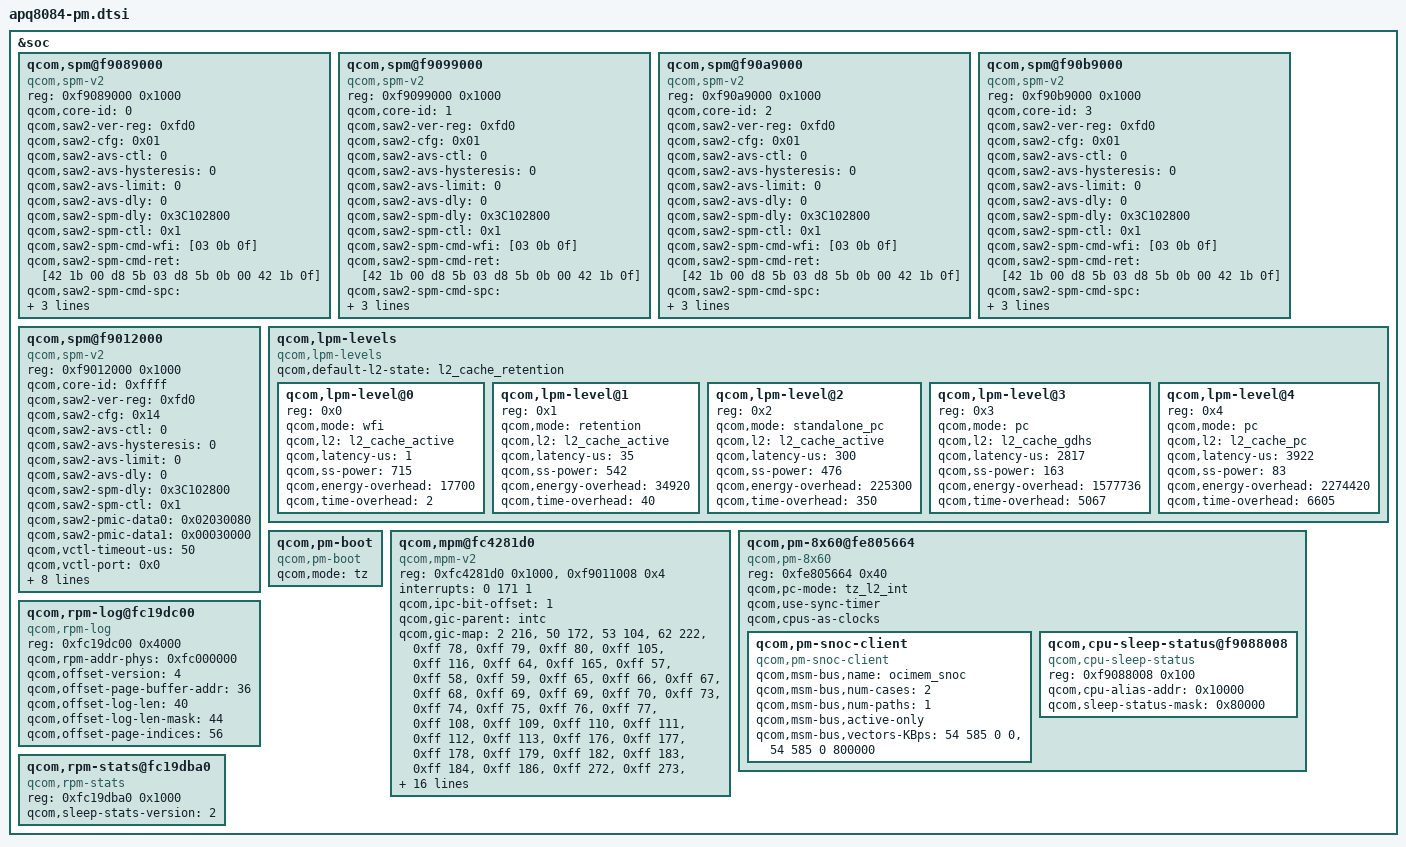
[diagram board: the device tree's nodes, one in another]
/* Copyright (c) 2013, The Linux Foundation. All rights reserved.
 *
 * This program is free software; you can redistribute it and/or modify
 * it under the terms of the GNU General Public License version 2 and
 * only version 2 as published by the Free Software Foundation.
 *
 * This program is distributed in the hope that it will be useful,
 * but WITHOUT ANY WARRANTY; without even the implied warranty of
 * MERCHANTABILITY or FITNESS FOR A PARTICULAR PURPOSE.  See the
 * GNU General Public License for more details.
 */

&soc {
	qcom,spm@f9089000 {
		compatible = "qcom,spm-v2";
	#address-cells = <1>;
	#size-cells = <1>;
		reg = <0xf9089000 0x1000>;
		qcom,core-id = <0>;
		qcom,saw2-ver-reg = <0xfd0>;
		qcom,saw2-cfg = <0x01>;
		qcom,saw2-avs-ctl = <0>;
		qcom,saw2-avs-hysteresis = <0>;
		qcom,saw2-avs-limit = <0>;
		qcom,saw2-avs-dly= <0>;
		qcom,saw2-spm-dly= <0x3C102800>;
		qcom,saw2-spm-ctl = <0x1>;
		qcom,saw2-spm-cmd-wfi = [03 0b 0f];
		qcom,saw2-spm-cmd-ret = [42 1b 00 d8 5b 03 d8 5b 0b 00 42 1b 0f];
		qcom,saw2-spm-cmd-spc = [00 20 80 10 e8 5b 03 3b e8 5b 82
				10 0b 30 06 26 30 0f];
		qcom,saw2-spm-cmd-pc = [00 20 80 10 e8 5b 03 3b e8 5b 82
				10 0b 30 06 26 30 0f];
	};

	qcom,spm@f9099000 {
		compatible = "qcom,spm-v2";
		#address-cells = <1>;
		#size-cells = <1>;
		reg = <0xf9099000 0x1000>;
		qcom,core-id = <1>;
		qcom,saw2-ver-reg = <0xfd0>;
		qcom,saw2-cfg = <0x01>;
		qcom,saw2-avs-ctl = <0>;
		qcom,saw2-avs-hysteresis = <0>;
		qcom,saw2-avs-limit = <0>;
		qcom,saw2-avs-dly= <0>;
		qcom,saw2-spm-dly= <0x3C102800>;
		qcom,saw2-spm-ctl = <0x1>;
		qcom,saw2-spm-cmd-wfi = [03 0b 0f];
		qcom,saw2-spm-cmd-ret = [42 1b 00 d8 5b 03 d8 5b 0b 00 42 1b 0f];
		qcom,saw2-spm-cmd-spc = [00 20 80 10 e8 5b 03 3b e8 5b 82
				10 0b 30 06 26 30 0f];
		qcom,saw2-spm-cmd-pc = [00 20 80 10 e8 5b 03 3b e8 5b 82
				10 0b 30 06 26 30 0f];
	};

	qcom,spm@f90a9000 {
		compatible = "qcom,spm-v2";
		#address-cells = <1>;
		#size-cells = <1>;
		reg = <0xf90a9000 0x1000>;
		qcom,core-id = <2>;
		qcom,saw2-ver-reg = <0xfd0>;
		qcom,saw2-cfg = <0x01>;
		qcom,saw2-avs-ctl = <0>;
		qcom,saw2-avs-hysteresis = <0>;
		qcom,saw2-avs-limit = <0>;
		qcom,saw2-avs-dly= <0>;
		qcom,saw2-spm-dly= <0x3C102800>;
		qcom,saw2-spm-ctl = <0x1>;
		qcom,saw2-spm-cmd-wfi = [03 0b 0f];
		qcom,saw2-spm-cmd-ret = [42 1b 00 d8 5b 03 d8 5b 0b 00 42 1b 0f];
		qcom,saw2-spm-cmd-spc = [00 20 80 10 e8 5b 03 3b e8 5b 82
				10 0b 30 06 26 30 0f];
		qcom,saw2-spm-cmd-pc = [00 20 80 10 e8 5b 03 3b e8 5b 82
				10 0b 30 06 26 30 0f];
	};

	qcom,spm@f90b9000 {
		compatible = "qcom,spm-v2";
		#address-cells = <1>;
		#size-cells = <1>;
		reg = <0xf90b9000 0x1000>;
		qcom,core-id = <3>;
		qcom,saw2-ver-reg = <0xfd0>;
		qcom,saw2-cfg = <0x01>;
		qcom,saw2-avs-ctl = <0>;
		qcom,saw2-avs-hysteresis = <0>;
		qcom,saw2-avs-limit = <0>;
		qcom,saw2-avs-dly= <0>;
		qcom,saw2-spm-dly= <0x3C102800>;
		qcom,saw2-spm-ctl = <0x1>;
		qcom,saw2-spm-cmd-wfi = [03 0b 0f];
		qcom,saw2-spm-cmd-ret = [42 1b 00 d8 5b 03 d8 5b 0b 00 42 1b 0f];
		qcom,saw2-spm-cmd-spc = [00 20 80 10 e8 5b 03 3b e8 5b 82
				10 0b 30 06 26 30 0f];
		qcom,saw2-spm-cmd-pc = [00 20 80 10 e8 5b 03 3b e8 5b 82
				10 0b 30 06 26 30 0f];
	};

	qcom,spm@f9012000 {
		compatible = "qcom,spm-v2";
		#address-cells = <1>;
		#size-cells = <1>;
		reg = <0xf9012000 0x1000>;
		qcom,core-id = <0xffff>; /* L2/APCS SAW */
		qcom,saw2-ver-reg = <0xfd0>;
		qcom,saw2-cfg = <0x14>;
		qcom,saw2-avs-ctl = <0>;
		qcom,saw2-avs-hysteresis = <0>;
		qcom,saw2-avs-limit = <0>;
		qcom,saw2-avs-dly= <0>;
		qcom,saw2-spm-dly= <0x3C102800>;
		qcom,saw2-spm-ctl = <0x1>;
		qcom,saw2-pmic-data0 = <0x02030080>;
		qcom,saw2-pmic-data1 = <0x00030000>;
		qcom,vctl-timeout-us = <50>;
		qcom,vctl-port = <0x0>;
		qcom,phase-port = <0x1>;
		qcom,pfm-port = <0x2>;
		qcom,saw2-spm-cmd-ret = [1f 00 20 03 22 00 0f];
		qcom,saw2-spm-cmd-gdhs = [00 20 32 42 07 44 22 50 02 32 50 0f];
		qcom,saw2-spm-cmd-pc = [00 22 12 32 b0 11 42 07 01 b0 12 22
				44 50 02 32 50 0f];
		qcom,L2-spm-is-apcs-master;
	};

	qcom,lpm-levels {
		compatible = "qcom,lpm-levels";
		qcom,default-l2-state = "l2_cache_retention";
		#address-cells = <1>;
		#size-cells = <0>;

		qcom,lpm-level@0 {
			reg = <0x0>;
			qcom,mode = "wfi";
			qcom,l2 = "l2_cache_active";
			qcom,latency-us = <1>;
			qcom,ss-power = <715>;
			qcom,energy-overhead = <17700>;
			qcom,time-overhead = <2>;
		};

		qcom,lpm-level@1 {
			reg = <0x1>;
			qcom,mode = "retention";
			qcom,l2 = "l2_cache_active";
			qcom,latency-us = <35>;
			qcom,ss-power = <542>;
			qcom,energy-overhead = <34920>;
			qcom,time-overhead = <40>;
		};


		qcom,lpm-level@2 {
			reg = <0x2>;
			qcom,mode = "standalone_pc";
			qcom,l2 = "l2_cache_active";
			qcom,latency-us = <300>;
			qcom,ss-power = <476>;
			qcom,energy-overhead = <225300>;
			qcom,time-overhead = <350>;
		};

		qcom,lpm-level@3 {
			reg = <0x3>;
			qcom,mode = "pc";
			qcom,l2 = "l2_cache_gdhs";
			qcom,latency-us = <2817>;
			qcom,ss-power = <163>;
			qcom,energy-overhead = <1577736>;
			qcom,time-overhead = <5067>;
		};

		qcom,lpm-level@4 {
			reg = <0x4>;
			qcom,mode = "pc";
			qcom,l2 = "l2_cache_pc";
			qcom,latency-us = <3922>;
			qcom,ss-power = <83>;
			qcom,energy-overhead = <2274420>;
			qcom,time-overhead = <6605>;
		};
	};

	qcom,pm-boot {
		compatible = "qcom,pm-boot";
		qcom,mode = "tz";
	};

	qcom,mpm@fc4281d0 {
		compatible = "qcom,mpm-v2";
		reg = <0xfc4281d0 0x1000>, /* MSM_RPM_MPM_BASE 4K */
		    <0xf9011008 0x4>;   /* MSM_APCS_GCC_BASE 4K */
		reg-names = "vmpm", "ipc";
		interrupts = <0 171 1>;

		qcom,ipc-bit-offset = <1>;

		qcom,gic-parent = <&intc>;
		qcom,gic-map = <2 216>, /* tsens_upper_lower_int */
			<50 172>, /* usb1_hs_async_wakeup_irq */
			<53 104>, /* mdss_irq */
			<62 222>, /* ee0_krait_hlos_spmi_periph_irq */
			<0xff 78>, /* mdss_mmu_cirpt[0] */
			<0xff 79>, /* mdss_mmu_cirpt[1] */
			<0xff 80>, /* mdss_mmu_cirpt[2] */
			<0xff 105>, /* mdss_mmu_pmirpt */
			<0xff 116>, /* mdss_vbif_irpt */
			<0xff 64>, /* usb30_hsic_ee1_irq */
			<0xff 165>, /* usb30_hs_phy_irq */

			<0xff 57>, /* o_vpu_vpu_apps_irq_out */
			<0xff 58>, /* o_vpu_maple_apps_irq_out */
			<0xff 59>, /* o_avsync_cpu_int0 */
			<0xff 65>, /* o_gc_sys_irq[0] */
			<0xff 66>, /* o_gc_sys_irq[1] */
			<0xff 67>, /* o_gc_sys_irq[2] */
			<0xff 68>, /* o_gc_sys_irq[3] */
			<0xff 69>, /* oxili_vbif_irpt */
			<0xff 69>, /* oxili_vbif_irpt */
			<0xff 70>, /* oxili_mmu_pmirpt */
			<0xff 73>, /* venus0_mmu_cirpt[2] */
			<0xff 74>, /* venus0_mmu_cirpt[1] */
			<0xff 75>, /* venus0_mmu_cirpt[0] */
			<0xff 76>, /* venus0_irq */
			<0xff 77>, /* venus0_mmu_pmirpt */
			<0xff 108>, /* ocmem_nonsec_irq */
			<0xff 109>, /* ocmem_dm_nonsec_irq */
			<0xff 110>, /* csiphy_0_irq */
			<0xff 111>, /* csiphy_1_irq */
			<0xff 112>, /* csiphy_2_irq */
			<0xff 113>, /* o_ocmem_axi_timeout_nonseq_irq */
			<0xff 176>, /* o_vpu_vbif_mmu_cirpt[0] */
			<0xff 177>, /* o_vpu_vbif_mmu_cirpt[1] */
			<0xff 178>, /* o_vpu_vbif_mmu_cirpt[2] */
			<0xff 179>, /* o_vpu_vbif_mmu_pmirpt */
			<0xff 182>, /* rbif_irq[0] */
			<0xff 183>, /* rbif_irq[1] */
			<0xff 184>, /* rbif_irq[2] */
			<0xff 186>, /* mnoc_obs_mainFault */
			<0xff 272>, /* oxili_mmu_cirpt[0] */
			<0xff 273>, /* oxili_mmu_cirpt[1] */
			<0xff 274>, /* oxili_mmu_cirpt[2] */

			<0xff 168>, /* lpass_irq_out_apcs[11] */
			<0xff 188>, /* lpass_irq_out_apcs(0) */
			<0xff 189>, /* lpass_irq_out_apcs(1) */
			<0xff 190>, /* lpass_irq_out_apcs(2) */
			<0xff 191>, /* lpass_irq_out_apcs(3) */
			<0xff 192>, /* lpass_irq_out_apcs(4) */
			<0xff 193>, /* lpass_irq_out_apcs(5) */
			<0xff 194>, /* lpass_irq_out_apcs(6) */
			<0xff 195>, /* lpass_irq_out_apcs(7) */
			<0xff 196>, /* lpass_irq_out_apcs(8) */
			<0xff 197>, /* lpass_irq_out_apcs(9) */
			<0xff 198>, /* lpass_irq_out_apcs[19] */
			<0xff 212>, /* lpass_irq_out_apcs[16] */
			<0xff 234>, /* lpass_irq_out_apcs[23] */
			<0xff 235>, /* lpass_irq_out_apcs[20] */
			<0xff 297>, /* lpass_irq_out_apcs[21] */
			<0xff 298>, /* lpass_irq_out_apcs[22] */
			<0xff 299>, /* lpass_irq_out_apcs[17] */
			<0xff 300>, /* lpass_irq_out_apcs[18] */
			<0xff 200>, /* rpm_ipc(4) */
			<0xff 201>, /* rpm_ipc(5) */
			<0xff 202>, /* rpm_ipc(6) */
			<0xff 203>, /* rpm_ipc(7) */
			<0xff 204>, /* rpm_ipc(24) */
			<0xff 205>, /* rpm_ipc(25) */
			<0xff 206>, /* rpm_ipc(26) */
			<0xff 207>, /* rpm_ipc(27) */
			<0xff 240>; /* summary_irq_kpss */

		qcom,gpio-parent = <&msmgpio>;
		qcom,gpio-map = <3 1>,
			<4 5>,
			<5 8>,
			<6 9>,
			<7 28>,
			<8 34>,
			<9 40>,
			<10 44>,
			<11 48>,
			<12 52>,
			<13 55>,
			<14 56>,
			<15 58>,
			<16 60>,
			<17 64>,
			<18 67>,
			<19 68>,
			<20 69>,
			<21 76>,
			<22 77>,
			<23 78>,
			<24 79>,
			<25 84>,
			<26 95>,
			<27 102>,
			<28 103>,
			<29 104>,
			<30 105>,
			<31 107>,
			<32 109>,
			<33 111>,
			<34 113>,
			<35 121>,
			<36 122>,
			<37 123>,
			<38 131>,
			<40 139>,
			<41 141>;
	};

	qcom,pm-8x60@fe805664 {
		compatible = "qcom,pm-8x60";
		#address-cells = <1>;
		#size-cells = <1>;
		ranges;
		reg = <0xfe805664 0x40>;
		qcom,pc-mode = "tz_l2_int";
		qcom,use-sync-timer;
		qcom,cpus-as-clocks;

		qcom,pm-snoc-client {
			compatible = "qcom,pm-snoc-client";
			qcom,msm-bus,name = "ocimem_snoc";
			qcom,msm-bus,num-cases = <2>;
			qcom,msm-bus,num-paths = <1>;
			qcom,msm-bus,active-only;
			qcom,msm-bus,vectors-KBps =
				<54 585 0 0>,
				<54 585 0 800000>;
		};

		qcom,cpu-sleep-status@f9088008{
			compatible = "qcom,cpu-sleep-status";
			reg = <0xf9088008 0x100>;
			qcom,cpu-alias-addr = <0x10000>;
			qcom,sleep-status-mask= <0x80000>;
		};
	};

	qcom,rpm-log@fc19dc00 {
		compatible = "qcom,rpm-log";
		reg = <0xfc19dc00 0x4000>;
		qcom,rpm-addr-phys = <0xfc000000>;
		qcom,offset-version = <4>;
		qcom,offset-page-buffer-addr = <36>;
		qcom,offset-log-len = <40>;
		qcom,offset-log-len-mask = <44>;
		qcom,offset-page-indices = <56>;
	};

	qcom,rpm-stats@fc19dba0 {
		compatible = "qcom,rpm-stats";
		reg = <0xfc19dba0 0x1000>;
		reg-names = "phys_addr_base";
		qcom,sleep-stats-version = <2>;
	};
};

